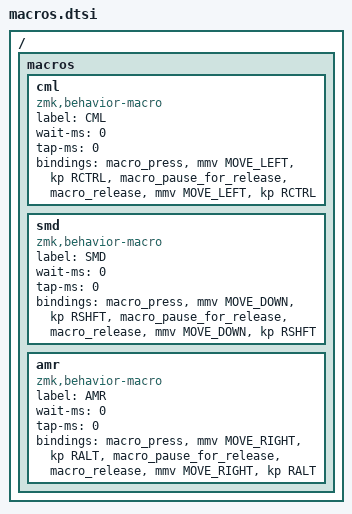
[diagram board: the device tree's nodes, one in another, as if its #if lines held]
/ {
  macros {
    // Charybdis-specific macros
    #ifdef CHARYBDIS
    #endif

    // Corne-specific macros
    #ifdef CORNE 
    cml: cml {
      compatible = "zmk,behavior-macro";
      label = "CML";
      #binding-cells = <0>;
      wait-ms = <0>;
      tap-ms = <0>;
      bindings = <&macro_press &mmv MOVE_LEFT &kp RCTRL>,
        <&macro_pause_for_release>,
        <&macro_release &mmv MOVE_LEFT &kp RCTRL>;
    };

    smd: smd {
      compatible = "zmk,behavior-macro";
      label = "SMD";
      #binding-cells = <0>;
      wait-ms = <0>;
      tap-ms = <0>;
      bindings = <&macro_press &mmv MOVE_DOWN &kp RSHFT>,
        <&macro_pause_for_release>,
        <&macro_release &mmv MOVE_DOWN &kp RSHFT>;
    };

    amr: amr {
      compatible = "zmk,behavior-macro";
      label = "AMR";
      #binding-cells = <0>;
      wait-ms = <0>;
      tap-ms = <0>;
      bindings = <&macro_press &mmv MOVE_RIGHT &kp RALT>,
        <&macro_pause_for_release>,
        <&macro_release &mmv MOVE_RIGHT &kp RALT>;
    };
    #endif
  };
};
